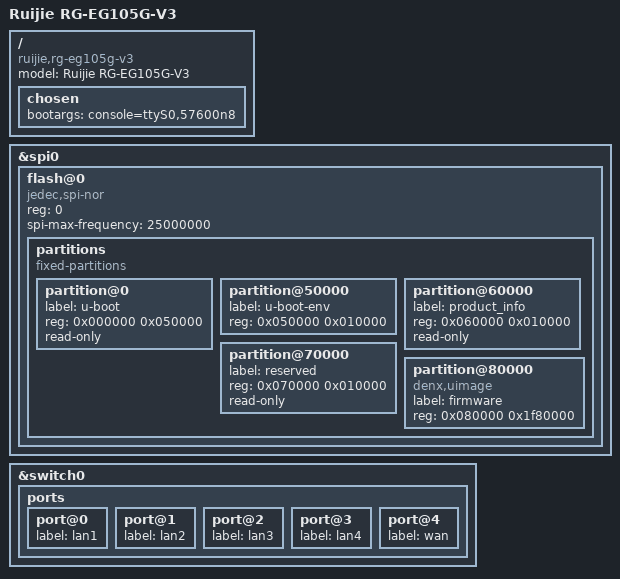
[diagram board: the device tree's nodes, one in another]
// SPDX-License-Identifier: GPL-2.0-or-later OR MIT

#include "mt7621.dtsi"

/ {
	compatible = "ruijie,rg-eg105g-v3", "mediatek,mt7621-soc";
	model = "Ruijie RG-EG105G-V3";

	chosen {
		bootargs = "console=ttyS0,57600n8";
	};
};

&spi0 {
	status = "okay";

	flash@0 {
		compatible = "jedec,spi-nor";
		reg = <0>;
		spi-max-frequency = <25000000>;

		partitions {
			compatible = "fixed-partitions";
			#address-cells = <1>;
			#size-cells = <1>;

			partition@0 {
				label = "u-boot";
				reg = <0x000000 0x050000>;
				read-only;
			};

			partition@50000 {
				label = "u-boot-env";
				reg = <0x050000 0x010000>;
			};

			partition@60000 {
				label = "product_info";
				reg = <0x060000 0x010000>;
				read-only;
			};

			partition@70000 {
				label = "reserved";
				reg = <0x070000 0x010000>;
				read-only;
			};

			partition@80000 {
				compatible = "denx,uimage";
				label = "firmware";
				reg = <0x080000 0x1f80000>;
			};
		};
	};
};

&switch0 {
	ports {
		port@0 {
			status = "okay";
			label = "lan1";
		};

		port@1 {
			status = "okay";
			label = "lan2";
		};

		port@2 {
			status = "okay";
			label = "lan3";
		};

		port@3 {
			status = "okay";
			label = "lan4";
		};

		port@4 {
			status = "okay";
			label = "wan";
		};
	};
};
